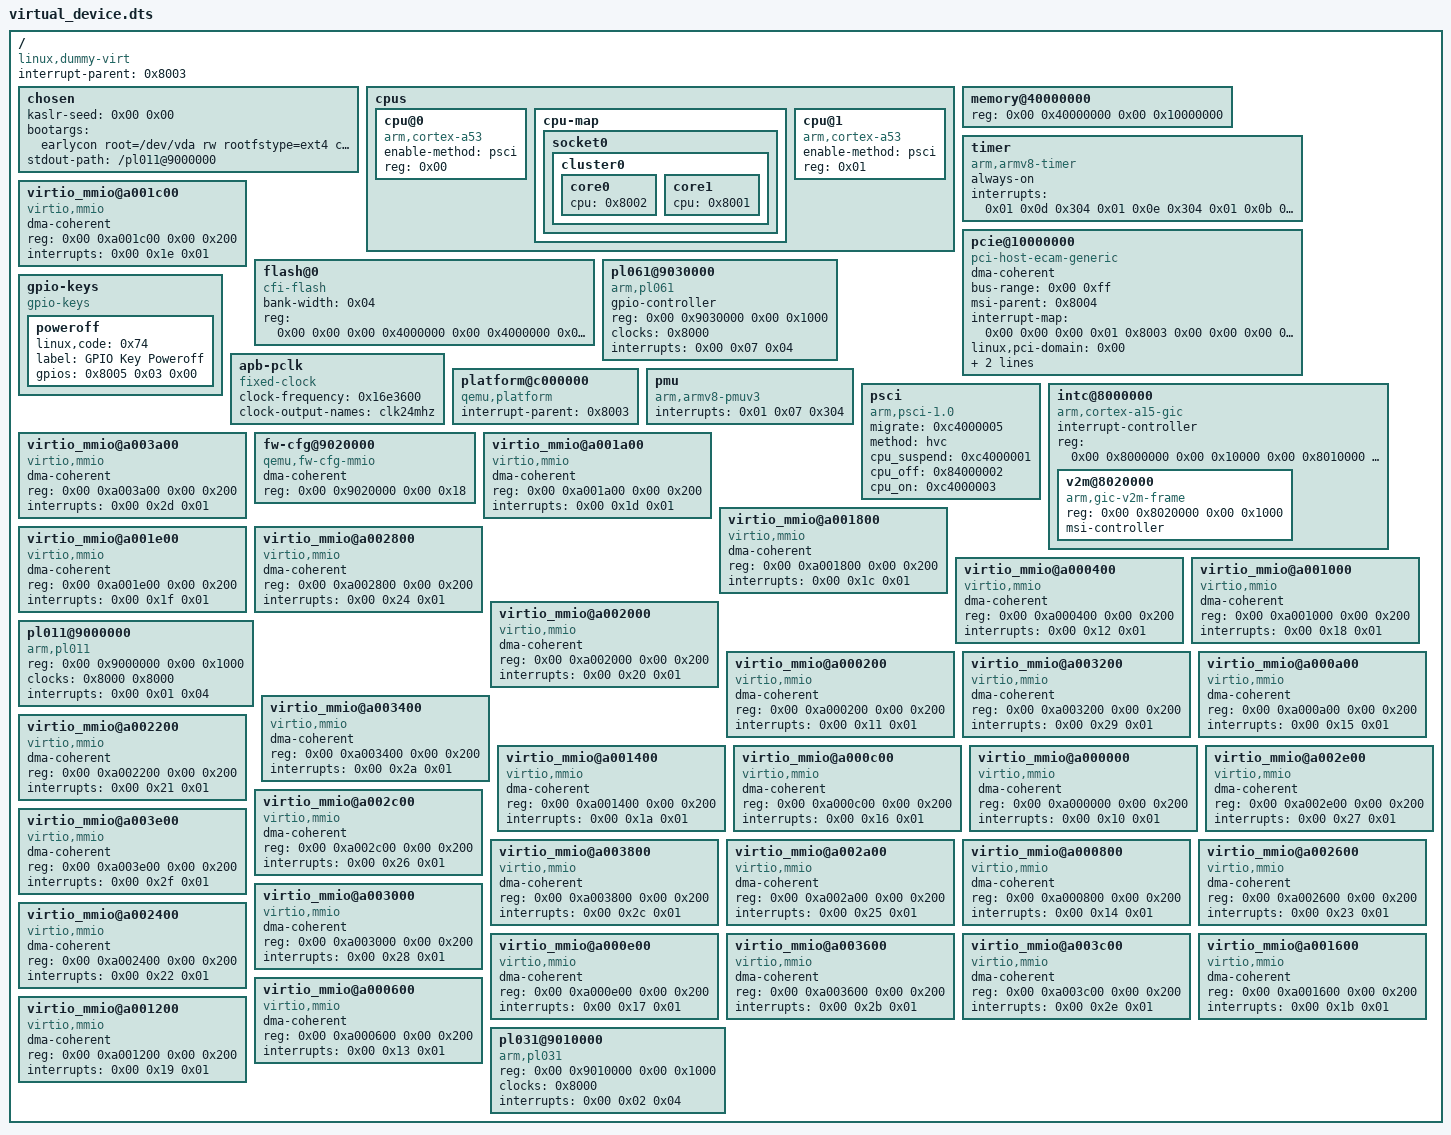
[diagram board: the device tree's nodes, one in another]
/*
 *  virtual_device.dts
 *  
 *  (C) 2024.12.04 <hkdywg@163.com>
 *
 *  This program is free software; you can redistribute it and/r modify
 *  it under the terms of the GNU General Public License version 2 as
 *  published by the Free Software Foundation.
 * */


/dts-v1/;

/ {
	#size-cells = <0x02>;
	#address-cells = <0x02>;
	interrupt-parent = <0x8003>;
	compatible = "linux,dummy-virt";

	chosen {
		kaslr-seed = <0x00 0x00>;
		bootargs = "earlycon root=/dev/vda rw rootfstype=ext4 console=ttyAMA0 init=/linuxrc loglevel=8 crashkernel=256M";
		stdout-path = "/pl011@9000000";
	};

	cpus {
		#size-cells = <0x00>;
		#address-cells = <0x01>;

		cpu@0 {
			device_type = "cpu";
			phandle = <0x8002>;
			enable-method = "psci";
			reg = <0x00>;
			compatible = "arm,cortex-a53";
		};

		cpu-map {
			socket0 {
				cluster0 {
					core0 {
						cpu = <0x8002>;
					};
					core1 {
						cpu = <0x8001>;
					};
				};
			};
		};

		cpu@1 {
			device_type = "cpu";
			phandle = <0x8001>;
			enable-method = "psci";
			reg = <0x01>;
			compatible = "arm,cortex-a53";
		};
	};

	memory@40000000 {
		device_type = "memory";
		reg = <0x00 0x40000000 0x00 0x10000000>;
	};

	timer {
		always-on;
		interrupts = <0x01 0x0d 0x304 0x01 0x0e 0x304 0x01 0x0b 0x304 0x01 0x0a 0x304>;
		compatible = "arm,armv8-timer\0arm,armv7-timer";
	};

	virtio_mmio@a001c00 {
		dma-coherent;
		reg = <0x00 0xa001c00 0x00 0x200>;
		interrupts = <0x00 0x1e 0x01>;
		compatible = "virtio,mmio";
	};

	pcie@10000000 {
		device_type = "pci";
		dma-coherent;
		bus-range = <0x00 0xff>;
		#size-cells = <0x02>;
		msi-parent = <0x8004>;
		#interrupt-cells = <0x01>;
		ranges = <0x1000000 0x00 0x00 0x00 0x3eff0000 0x00 0x10000 0x2000000 0x00 0x10000000 0x00 0x10000000 0x00 0x2eff0000 0x3000000 0x80 0x00 0x80 0x00 0x80 0x00>;
		interrupt-map = <0x00 0x00 0x00 0x01 0x8003 0x00 0x00 0x00 0x03 0x04 0x00 0x00 0x00 0x02 0x8003 0x00 0x00 0x00 0x04 0x04 0x00 0x00 0x00 0x03 0x8003 0x00 0x00 0x00 0x05 0x04 0x00 0x00 0x00 0x04 0x8003 0x00 0x00 0x00 0x06 0x04 0x800 0x00 0x00 0x01 0x8003 0x00 0x00 0x00 0x04 0x04 0x800 0x00 0x00 0x02 0x8003 0x00 0x00 0x00 0x05 0x04 0x800 0x00 0x00 0x03 0x8003 0x00 0x00 0x00 0x06 0x04 0x800 0x00 0x00 0x04 0x8003 0x00 0x00 0x00 0x03 0x04 0x1000 0x00 0x00 0x01 0x8003 0x00 0x00 0x00 0x05 0x04 0x1000 0x00 0x00 0x02 0x8003 0x00 0x00 0x00 0x06 0x04 0x1000 0x00 0x00 0x03 0x8003 0x00 0x00 0x00 0x03 0x04 0x1000 0x00 0x00 0x04 0x8003 0x00 0x00 0x00 0x04 0x04 0x1800 0x00 0x00 0x01 0x8003 0x00 0x00 0x00 0x06 0x04 0x1800 0x00 0x00 0x02 0x8003 0x00 0x00 0x00 0x03 0x04 0x1800 0x00 0x00 0x03 0x8003 0x00 0x00 0x00 0x04 0x04 0x1800 0x00 0x00 0x04 0x8003 0x00 0x00 0x00 0x05 0x04>;
		#address-cells = <0x03>;
		linux,pci-domain = <0x00>;
		interrupt-map-mask = <0x1800 0x00 0x00 0x07>;
		reg = <0x40 0x10000000 0x00 0x10000000>;
		compatible = "pci-host-ecam-generic";
	};

	flash@0 {
		bank-width = <0x04>;
		reg = <0x00 0x00 0x00 0x4000000 0x00 0x4000000 0x00 0x4000000>;
		compatible = "cfi-flash";
	};

	pl061@9030000 {
		#gpio-cells = <0x02>;
		clock-names = "apb_pclk";
		phandle = <0x8005>;
		gpio-controller;
		reg = <0x00 0x9030000 0x00 0x1000>;
		clocks = <0x8000>;
		interrupts = <0x00 0x07 0x04>;
		compatible = "arm,pl061\0arm,primecell";
	};

	gpio-keys {
		compatible = "gpio-keys";

		poweroff {
			linux,code = <0x74>;
			label = "GPIO Key Poweroff";
			gpios = <0x8005 0x03 0x00>;
		};
	};

	apb-pclk {
		#clock-cells = <0x00>;
		phandle = <0x8000>;
		clock-frequency = <0x16e3600>;
		compatible = "fixed-clock";
		clock-output-names = "clk24mhz";
	};

	platform@c000000 {
		#size-cells = <0x01>;
		ranges = <0x00 0x00 0xc000000 0x2000000>;
		#address-cells = <0x01>;
		interrupt-parent = <0x8003>;
		compatible = "qemu,platform\0simple-bus";
	};

	pmu {
		interrupts = <0x01 0x07 0x304>;
		compatible = "arm,armv8-pmuv3";
	};

	psci {
		migrate = <0xc4000005>;
		method = "hvc";
		cpu_suspend = <0xc4000001>;
		cpu_off = <0x84000002>;
		cpu_on = <0xc4000003>;
		compatible = "arm,psci-1.0\0arm,psci-0.2\0arm,psci";
	};

	intc@8000000 {
		phandle = <0x8003>;
		interrupt-controller;
		#size-cells = <0x02>;
		#interrupt-cells = <0x03>;
		ranges;
		#address-cells = <0x02>;
		reg = <0x00 0x8000000 0x00 0x10000 0x00 0x8010000 0x00 0x10000>;
		compatible = "arm,cortex-a15-gic";

		v2m@8020000 {
			phandle = <0x8004>;
			reg = <0x00 0x8020000 0x00 0x1000>;
			msi-controller;
			compatible = "arm,gic-v2m-frame";
		};
	};

	virtio_mmio@a003a00 {
		dma-coherent;
		reg = <0x00 0xa003a00 0x00 0x200>;
		interrupts = <0x00 0x2d 0x01>;
		compatible = "virtio,mmio";
	};

	fw-cfg@9020000 {
		dma-coherent;
		reg = <0x00 0x9020000 0x00 0x18>;
		compatible = "qemu,fw-cfg-mmio";
	};

	virtio_mmio@a001a00 {
		dma-coherent;
		reg = <0x00 0xa001a00 0x00 0x200>;
		interrupts = <0x00 0x1d 0x01>;
		compatible = "virtio,mmio";
	};

	virtio_mmio@a001800 {
		dma-coherent;
		reg = <0x00 0xa001800 0x00 0x200>;
		interrupts = <0x00 0x1c 0x01>;
		compatible = "virtio,mmio";
	};

	virtio_mmio@a001e00 {
		dma-coherent;
		reg = <0x00 0xa001e00 0x00 0x200>;
		interrupts = <0x00 0x1f 0x01>;
		compatible = "virtio,mmio";
	};

	virtio_mmio@a002800 {
		dma-coherent;
		reg = <0x00 0xa002800 0x00 0x200>;
		interrupts = <0x00 0x24 0x01>;
		compatible = "virtio,mmio";
	};


	virtio_mmio@a000400 {
		dma-coherent;
		reg = <0x00 0xa000400 0x00 0x200>;
		interrupts = <0x00 0x12 0x01>;
		compatible = "virtio,mmio";
	};

	virtio_mmio@a001000 {
		dma-coherent;
		reg = <0x00 0xa001000 0x00 0x200>;
		interrupts = <0x00 0x18 0x01>;
		compatible = "virtio,mmio";
	};

	virtio_mmio@a002000 {
		dma-coherent;
		reg = <0x00 0xa002000 0x00 0x200>;
		interrupts = <0x00 0x20 0x01>;
		compatible = "virtio,mmio";
	};

	pl011@9000000 {
		clock-names = "uartclk\0apb_pclk";
		reg = <0x00 0x9000000 0x00 0x1000>;
		clocks = <0x8000 0x8000>;
		interrupts = <0x00 0x01 0x04>;
		compatible = "arm,pl011\0arm,primecell";
	};

	virtio_mmio@a000200 {
		dma-coherent;
		reg = <0x00 0xa000200 0x00 0x200>;
		interrupts = <0x00 0x11 0x01>;
		compatible = "virtio,mmio";
	};

	virtio_mmio@a003200 {
		dma-coherent;
		reg = <0x00 0xa003200 0x00 0x200>;
		interrupts = <0x00 0x29 0x01>;
		compatible = "virtio,mmio";
	};

	virtio_mmio@a000a00 {
		dma-coherent;
		reg = <0x00 0xa000a00 0x00 0x200>;
		interrupts = <0x00 0x15 0x01>;
		compatible = "virtio,mmio";
	};

	virtio_mmio@a003400 {
		dma-coherent;
		reg = <0x00 0xa003400 0x00 0x200>;
		interrupts = <0x00 0x2a 0x01>;
		compatible = "virtio,mmio";
	};

	virtio_mmio@a002200 {
		dma-coherent;
		reg = <0x00 0xa002200 0x00 0x200>;
		interrupts = <0x00 0x21 0x01>;
		compatible = "virtio,mmio";
	};

	virtio_mmio@a001400 {
		dma-coherent;
		reg = <0x00 0xa001400 0x00 0x200>;
		interrupts = <0x00 0x1a 0x01>;
		compatible = "virtio,mmio";
	};

	virtio_mmio@a000c00 {
		dma-coherent;
		reg = <0x00 0xa000c00 0x00 0x200>;
		interrupts = <0x00 0x16 0x01>;
		compatible = "virtio,mmio";
	};

	virtio_mmio@a000000 {
		dma-coherent;
		reg = <0x00 0xa000000 0x00 0x200>;
		interrupts = <0x00 0x10 0x01>;
		compatible = "virtio,mmio";
	};

	virtio_mmio@a002e00 {
		dma-coherent;
		reg = <0x00 0xa002e00 0x00 0x200>;
		interrupts = <0x00 0x27 0x01>;
		compatible = "virtio,mmio";
	};

	virtio_mmio@a002c00 {
		dma-coherent;
		reg = <0x00 0xa002c00 0x00 0x200>;
		interrupts = <0x00 0x26 0x01>;
		compatible = "virtio,mmio";
	};


	virtio_mmio@a003e00 {
		dma-coherent;
		reg = <0x00 0xa003e00 0x00 0x200>;
		interrupts = <0x00 0x2f 0x01>;
		compatible = "virtio,mmio";
	};


	virtio_mmio@a003800 {
		dma-coherent;
		reg = <0x00 0xa003800 0x00 0x200>;
		interrupts = <0x00 0x2c 0x01>;
		compatible = "virtio,mmio";
	};

	virtio_mmio@a002a00 {
		dma-coherent;
		reg = <0x00 0xa002a00 0x00 0x200>;
		interrupts = <0x00 0x25 0x01>;
		compatible = "virtio,mmio";
	};


	virtio_mmio@a000800 {
		dma-coherent;
		reg = <0x00 0xa000800 0x00 0x200>;
		interrupts = <0x00 0x14 0x01>;
		compatible = "virtio,mmio";
	};

	virtio_mmio@a002600 {
		dma-coherent;
		reg = <0x00 0xa002600 0x00 0x200>;
		interrupts = <0x00 0x23 0x01>;
		compatible = "virtio,mmio";
	};

	virtio_mmio@a003000 {
		dma-coherent;
		reg = <0x00 0xa003000 0x00 0x200>;
		interrupts = <0x00 0x28 0x01>;
		compatible = "virtio,mmio";
	};


	virtio_mmio@a002400 {
		dma-coherent;
		reg = <0x00 0xa002400 0x00 0x200>;
		interrupts = <0x00 0x22 0x01>;
		compatible = "virtio,mmio";
	};


	virtio_mmio@a000e00 {
		dma-coherent;
		reg = <0x00 0xa000e00 0x00 0x200>;
		interrupts = <0x00 0x17 0x01>;
		compatible = "virtio,mmio";
	};

	virtio_mmio@a003600 {
		dma-coherent;
		reg = <0x00 0xa003600 0x00 0x200>;
		interrupts = <0x00 0x2b 0x01>;
		compatible = "virtio,mmio";
	};

	virtio_mmio@a003c00 {
		dma-coherent;
		reg = <0x00 0xa003c00 0x00 0x200>;
		interrupts = <0x00 0x2e 0x01>;
		compatible = "virtio,mmio";
	};

	virtio_mmio@a001600 {
		dma-coherent;
		reg = <0x00 0xa001600 0x00 0x200>;
		interrupts = <0x00 0x1b 0x01>;
		compatible = "virtio,mmio";
	};

	virtio_mmio@a000600 {
		dma-coherent;
		reg = <0x00 0xa000600 0x00 0x200>;
		interrupts = <0x00 0x13 0x01>;
		compatible = "virtio,mmio";
	};

	virtio_mmio@a001200 {
		dma-coherent;
		reg = <0x00 0xa001200 0x00 0x200>;
		interrupts = <0x00 0x19 0x01>;
		compatible = "virtio,mmio";
	};

	pl031@9010000 {
		clock-names = "apb_pclk";
		reg = <0x00 0x9010000 0x00 0x1000>;
		clocks = <0x8000>;
		interrupts = <0x00 0x02 0x04>;
		compatible = "arm,pl031\0arm,primecell";
	};
};
